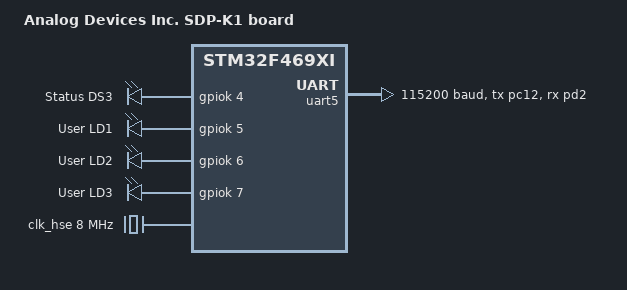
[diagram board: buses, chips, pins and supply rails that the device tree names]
/*
 * Copyright (c) 2024 BayLibre
 *
 * SPDX-License-Identifier: Apache-2.0
 */

/dts-v1/;
#include <st/f4/stm32f469Xi.dtsi>
#include <st/f4/stm32f469nihx-pinctrl.dtsi>
#include "arduino_r3_connector.dtsi"

/ {
	model = "Analog Devices Inc. SDP-K1 board";
	compatible = "adi,sdp-k1";

	chosen {
		zephyr,console = &uart5;
		zephyr,shell-uart = &uart5;
		zephyr,sram = &sram0;
		zephyr,flash = &flash0;
		zephyr,ccm = &ccm0;
	};

	leds {
		compatible = "gpio-leds";
		status_led: led_ds3 {
			gpios = <&gpiok 4 GPIO_ACTIVE_HIGH>;
			label = "Status DS3";
		};
		green_led_1: led_ds4 {
			gpios = <&gpiok 5 GPIO_ACTIVE_HIGH>;
			label = "User LD1";
		};
		orange_led_2: led_ds5 {
			gpios = <&gpiok 6 GPIO_ACTIVE_HIGH>;
			label = "User LD2";
		};
		red_led_3: led_ds6 {
			gpios = <&gpiok 7 GPIO_ACTIVE_HIGH>;
			label = "User LD3";
		};
	};

	aliases {
		led0 = &status_led;
	};
};

&clk_lsi {
	status = "okay";
};

&clk_hse {
	clock-frequency = <DT_FREQ_M(8)>;
	status = "okay";
};

&pll {
	div-m = <8>;
	mul-n = <336>;
	div-p = <2>;
	div-q = <7>;
	clocks = <&clk_hse>;
	status = "okay";
};

&rcc {
	clocks = <&pll>;
	clock-frequency = <DT_FREQ_M(168)>;
	ahb-prescaler = <1>;
	apb1-prescaler = <4>;
	apb2-prescaler = <2>;
};

&uart5 {
	pinctrl-0 = <&uart5_tx_pc12 &uart5_rx_pd2>;
	pinctrl-names = "default";
	current-speed = <115200>;
	status = "okay";
};
